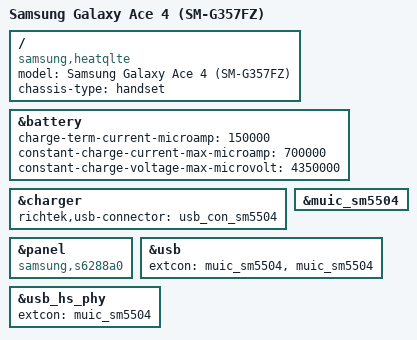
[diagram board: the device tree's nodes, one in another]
// SPDX-License-Identifier: GPL-2.0-only

/dts-v1/;

#include "msm8916-samsung-rossa-common.dtsi"

/* CYTTSP4 instead of IST3038 */
/delete-node/ &touchscreen;

/*
 * NOTE: The original firmware from Samsung can only boot ARM32 kernels.
 * Unfortunately, the firmware is signed and cannot be replaced easily.
 * There seems to be no way to boot ARM64 kernels on this device at the moment,
 * even though the hardware would support it.
 *
 * However, it is possible to use this device tree by compiling an ARM32 kernel
 * instead. For clarity and build testing this device tree is maintained next
 * to the other MSM8916 device trees. However, it is actually used through
 * arch/arm/boot/dts/qcom-msm8916-samsung-heatqlte.dts
 */

/ {
	model = "Samsung Galaxy Ace 4 (SM-G357FZ)";
	compatible = "samsung,heatqlte", "qcom,msm8916";
	chassis-type = "handset";
};

&battery {
	charge-term-current-microamp = <150000>;
	constant-charge-current-max-microamp = <700000>;
	constant-charge-voltage-max-microvolt = <4350000>;
};

&charger {
	richtek,usb-connector = <&usb_con_sm5504>;
	status = "okay";
};

&muic_sm5504 {
	status = "okay";
};

&panel {
	compatible = "samsung,s6288a0";
};

&usb {
	extcon = <&muic_sm5504>, <&muic_sm5504>;
	status = "okay";
};

&usb_hs_phy {
	extcon = <&muic_sm5504>;
};
